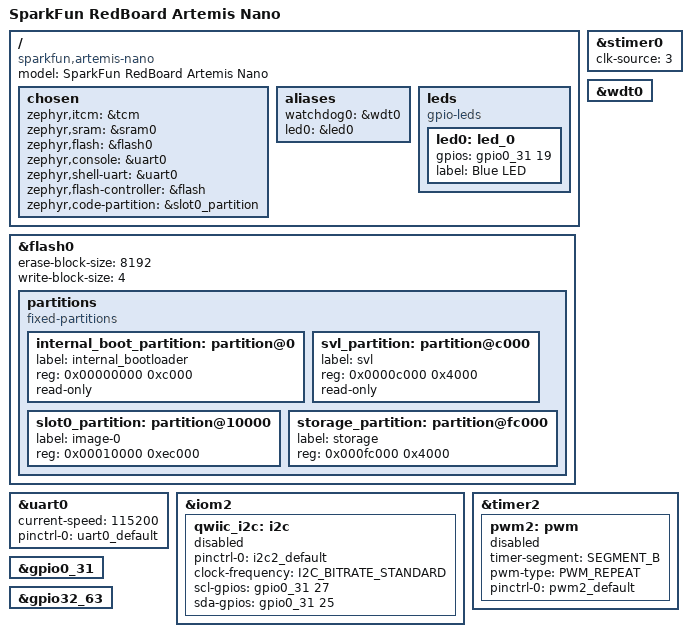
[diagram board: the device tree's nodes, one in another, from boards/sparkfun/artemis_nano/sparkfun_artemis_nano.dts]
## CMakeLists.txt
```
# SPDX-License-Identifier: Apache-2.0
#
# ArtemisNano_Hive_Turret_Test firmware. Adding the app directory to BOARD_ROOT
# makes boards/sparkfun/artemis_nano available as -b sparkfun_artemis_nano.

cmake_minimum_required(VERSION 3.20.0)
list(APPEND BOARD_ROOT ${CMAKE_CURRENT_SOURCE_DIR})
find_package(Zephyr REQUIRED HINTS $ENV{ZEPHYR_BASE})
project(artemis_turret)

target_sources(app PRIVATE src/main.c)
```

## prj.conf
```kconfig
# Phase 2: board bring-up. Console + LED only.
CONFIG_GPIO=y
CONFIG_PRINTK=y
```

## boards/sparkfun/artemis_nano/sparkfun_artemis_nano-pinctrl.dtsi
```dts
/*
 * SPDX-License-Identifier: Apache-2.0
 *
 * Pad assignments from SparkFun's RedBoard-Artemis-Nano.sch (see docs/wiring.html).
 */

#include <zephyr/dt-bindings/pinctrl/ambiq-apollo3-pinctrl.h>

&pinctrl {
	/* UART0 -> CH340E USB-serial (TXO-0 = pad 48, RXI-0 = pad 49) */
	uart0_default: uart0_default {
		group1 {
			pinmux = <UART0TX_P48>;
		};

		group2 {
			pinmux = <UART0RX_P49>;
			input-enable;
		};
	};

	/* SWO is shared with header pin A1 (pad 33) on this board */
	itm_default: itm_default {
		group1 {
			pinmux = <SWO_P33>;
		};
	};

	/* Qwiic connector: SCL2 = pad 27, SDA2 = pad 25 */
	i2c2_default: i2c2_default {
		group1 {
			pinmux = <M2SCL_P27>, <M2SDAWIR3_P25>;
			drive-open-drain;
			drive-strength = "0.5";
			bias-pull-up;
		};
	};

	/*
	 * Servo signal on header D9 = pad 39 (CTX25). With the driver's NORMAL output
	 * type, CTX25 can be driven by timer 2 segment B (B2OUT) or timer 6 segment A
	 * (A6OUT); see outcfg_tbl in hal_ambiq am_hal_ctimer.c. We use timer 2 seg B.
	 */
	pwm2_default: pwm2_default {
		group1 {
			pinmux = <CTIM25_P39>;
		};
	};
};
```

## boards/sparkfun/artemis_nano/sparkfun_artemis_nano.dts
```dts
/*
 * SPDX-License-Identifier: Apache-2.0
 *
 * SparkFun RedBoard Artemis Nano (DEV-15443), Artemis module = Ambiq Apollo3 Blue.
 * Derived from boards/ambiq/apollo3_evb (Zephyr v4.4.2).
 */

/dts-v1/;
#include <ambiq/ambiq_apollo3_blue.dtsi>

#include "sparkfun_artemis_nano-pinctrl.dtsi"

/ {
	model = "SparkFun RedBoard Artemis Nano";
	compatible = "sparkfun,artemis-nano";

	chosen {
		zephyr,itcm = &tcm;
		zephyr,sram = &sram0;
		zephyr,flash = &flash0;
		zephyr,console = &uart0;
		zephyr,shell-uart = &uart0;
		zephyr,flash-controller = &flash;
		zephyr,code-partition = &slot0_partition;
	};

	aliases {
		watchdog0 = &wdt0;
		led0 = &led0;
	};

	leds {
		compatible = "gpio-leds";

		/* Blue LED D1 on pad 19 via 1k to GND: active high */
		led0: led_0 {
			gpios = <&gpio0_31 19 GPIO_ACTIVE_HIGH>;
			label = "Blue LED";
		};
	};
};

&flash0 {
	erase-block-size = <8192>;
	write-block-size = <4>;

	partitions {
		compatible = "fixed-partitions";
		#address-cells = <1>;
		#size-cells = <1>;

		/* Ambiq secure bootloader: never write */
		internal_boot_partition: partition@0 {
			label = "internal_bootloader";
			reg = <0x00000000 0xc000>;
			read-only;
		};

		/* SparkFun Variable Loader (SVL): USB recovery path, never write */
		svl_partition: partition@c000 {
			label = "svl";
			reg = <0x0000c000 0x4000>;
			read-only;
		};

		/* Application, linked here via CONFIG_FLASH_LOAD_OFFSET=0x10000 */
		slot0_partition: partition@10000 {
			label = "image-0";
			reg = <0x00010000 0xec000>;
		};

		/* 16 KB at the end of the 1 MB flash */
		storage_partition: partition@fc000 {
			label = "storage";
			reg = <0x000fc000 0x4000>;
		};
	};
};

&stimer0 {
	clk-source = <3>;
};

&uart0 {
	current-speed = <115200>;
	pinctrl-0 = <&uart0_default>;
	pinctrl-names = "default";
	status = "okay";
};

&wdt0 {
	status = "okay";
};

/* Qwiic connector, off until a phase needs it */
&iom2 {
	qwiic_i2c: i2c {
		pinctrl-0 = <&i2c2_default>;
		pinctrl-names = "default";
		clock-frequency = <I2C_BITRATE_STANDARD>;
		scl-gpios = <&gpio0_31 27 (GPIO_OPEN_DRAIN | GPIO_PULL_UP)>;
		sda-gpios = <&gpio0_31 25 (GPIO_OPEN_DRAIN | GPIO_PULL_UP)>;
		status = "disabled";
	};
};

/*
 * Servo PWM on D9 (pad 39), timer 2 segment B. Off for phase 2; phase 3 enables it
 * and moves timer 2 to the 3 MHz clock so a 20 ms frame (60000 counts) fits in 16 bits.
 */
&timer2 {
	pwm2: pwm {
		timer-segment = "SEGMENT_B";
		pwm-type = "PWM_REPEAT";
		pinctrl-0 = <&pwm2_default>;
		pinctrl-names = "default";
		status = "disabled";
	};
};

/*
 * BLE (bleif / bt_hci_apollo) is left at the SoC default (disabled) until phase 4.
 * The EVB pinmuxes BLEIF onto pads 30-33, 35, 41; on this board 31/32/33/35 are
 * header pins A5/A15/A1/A14, so that needs checking before it is enabled.
 */

&gpio0_31 {
	status = "okay";
};

&gpio32_63 {
	status = "okay";
};
```

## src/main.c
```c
/*
 * SPDX-License-Identifier: Apache-2.0
 *
 * ArtemisNano_Hive_Turret_Test, phase 2 bring-up.
 *
 * Gate: blue LED lights at boot, console prints the banner, LED then blinks.
 *   LED on, no text -> boot is fine, console pins/baud are wrong.
 *   LED off         -> the image never ran (load address, SVL jump, clocks).
 */

#include <zephyr/kernel.h>
#include <zephyr/init.h>
#include <zephyr/sys/printk.h>
#include <zephyr/drivers/gpio.h>
#include <cmsis_core.h>
#include <am_mcu_apollo.h>

#define BLUE_LED_PAD 19

static const struct gpio_dt_spec led = GPIO_DT_SPEC_GET(DT_ALIAS(led0), gpios);

/* Runs before the kernel, drivers and console: drive the LED pad with the HAL. */
static int early_led_on(void)
{
	am_hal_gpio_pinconfig(BLUE_LED_PAD, g_AM_HAL_GPIO_OUTPUT);
	am_hal_gpio_output_set(BLUE_LED_PAD);
	return 0;
}
SYS_INIT(early_led_on, PRE_KERNEL_1, 0);

int main(void)
{
	printk("\n*** artemis_turret phase 2 on %s ***\n", CONFIG_BOARD_TARGET);
	printk("VTOR=0x%08x (expect 0x%08x)\n", (unsigned int)SCB->VTOR,
	       (unsigned int)CONFIG_FLASH_LOAD_OFFSET);

	if (!gpio_is_ready_dt(&led) || gpio_pin_configure_dt(&led, GPIO_OUTPUT_ACTIVE) < 0) {
		printk("led0 not ready\n");
		return 0;
	}

	for (uint32_t tick = 0;; tick++) {
		gpio_pin_toggle_dt(&led);
		if ((tick % 10) == 0) {
			printk("tick %u, uptime %lld ms\n", tick, k_uptime_get());
		}
		k_msleep(500);
	}
	return 0;
}
```
